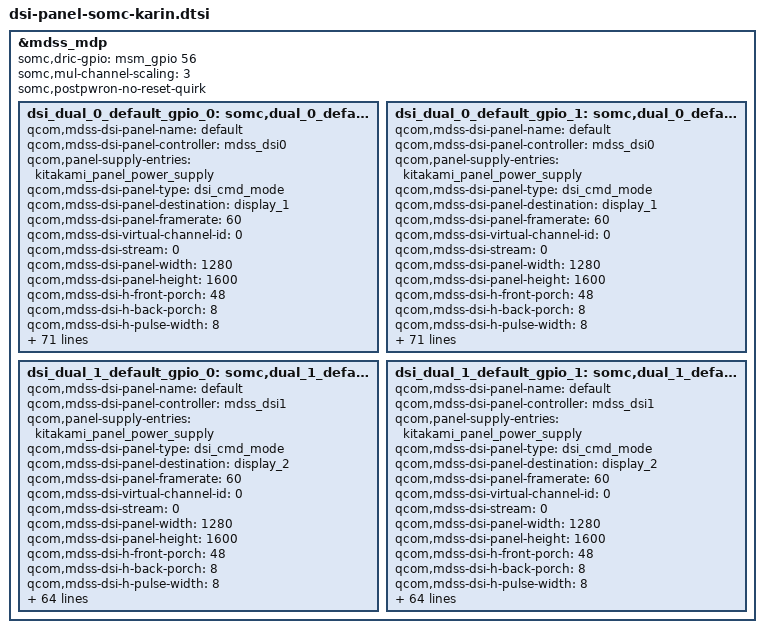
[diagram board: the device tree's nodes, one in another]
/* Copyright (c) 2013-2014, The Linux Foundation. All rights reserved.
 *
 * This program is free software; you can redistribute it and/or modify
 * it under the terms of the GNU General Public License version 2 and
 * only version 2 as published by the Free Software Foundation.
 *
 * This program is distributed in the hope that it will be useful,
 * but WITHOUT ANY WARRANTY; without even the implied warranty of
 * MERCHANTABILITY or FITNESS FOR A PARTICULAR PURPOSE.  See the
 * GNU General Public License for more details.
 */
/*
 * Copyright (C) 2015 Sony Mobile Communications Inc.
 *
 * This program is free software; you can redistribute it and/or modify
 * it under the terms of the GNU General Public License version 2, as
 * published by the Free Software Foundation.
 */

#include "dsi-panel-somc-novatek-jdi-uxga-cmd.dtsi"
#include "dsi-panel-somc-novatek-tianma-uxga-cmd.dtsi"

&mdss_mdp {
	somc,dric-gpio = <&msm_gpio 56 0>;
	somc,mul-channel-scaling = <3>;
	somc,postpwron-no-reset-quirk;
	dsi_dual_0_default_gpio_0: somc,dual_0_default_panel_0 {
		qcom,mdss-dsi-panel-name = "default";
		qcom,mdss-dsi-panel-controller = <&mdss_dsi0>;
		qcom,panel-supply-entries = <&kitakami_panel_power_supply>;
		qcom,mdss-dsi-panel-type = "dsi_cmd_mode";
		qcom,mdss-dsi-panel-destination = "display_1";
		qcom,mdss-dsi-panel-framerate = <60>;
		qcom,mdss-dsi-virtual-channel-id = <0>;
		qcom,mdss-dsi-stream = <0>;
		qcom,mdss-dsi-panel-width = <1280>;
		qcom,mdss-dsi-panel-height = <1600>;
		qcom,mdss-dsi-h-front-porch = <48>;
		qcom,mdss-dsi-h-back-porch = <8>;
		qcom,mdss-dsi-h-pulse-width = <8>;
		qcom,mdss-dsi-h-sync-skew = <0>;
		qcom,mdss-dsi-v-back-porch = <4>;
		qcom,mdss-dsi-v-front-porch = <246>;
		qcom,mdss-dsi-v-pulse-width = <4>;
		qcom,mdss-pan-physical-width-dimension = <216>;
		qcom,mdss-pan-physical-height-dimension = <135>;
		qcom,mdss-dsi-h-left-border = <0>;
		qcom,mdss-dsi-h-right-border = <0>;
		qcom,mdss-dsi-v-top-border = <0>;
		qcom,mdss-dsi-v-bottom-border = <0>;
		qcom,mdss-dsi-bpp = <24>;
		qcom,mdss-dsi-underflow-color = <0x0>;
		qcom,mdss-dsi-border-color = <0>;
		somc,mdss-dsi-init-command = [05 01 00 00 05 00 01 01
				23 01 00 00 00 00 02 B0 00
				29 01 00 00 00 00 06 B3 04 08 00 22 00
				23 01 00 00 00 00 02 B4 0C
				29 01 00 00 00 00 03 B6 3A D3
				23 01 00 00 00 00 02 C3 00
				23 01 00 00 00 00 02 D6 01
				15 01 00 00 00 00 02 3A 77
				39 01 00 00 00 00 05 2A 00 00 04 FF
				39 01 00 00 00 00 05 2B 00 00 06 3F
				15 01 00 00 00 00 02 35 00
				39 01 00 00 00 00 03 44 00 00
				05 01 00 00 64 00 01 11];
		qcom,mdss-dsi-on-command = [05 01 00 00 00 00 01 29];
		qcom,mdss-dsi-off-command = [05 01 00 00 14 00 01 28
				05 01 00 00 50 00 01 10];
		qcom,mdss-dsi-on-command-state = "dsi_lp_mode";
		qcom,mdss-dsi-off-command-state = "dsi_hs_mode";
		somc,mdss-dsi-touch-id-command = [06 01 00 01 05 00 01 A1];
		somc,mdss-dsi-touch-id-len = <7>;
		qcom,mdss-dsi-h-sync-pulse = <1>;
		qcom,mdss-dsi-traffic-mode = "non_burst_sync_event";
		qcom,mdss-dsi-bllp-eof-power-mode;
		qcom,mdss-dsi-bllp-power-mode;
		qcom,cmd-sync-wait-broadcast;
		qcom,mdss-dsi-lane-0-state;
		qcom,mdss-dsi-lane-1-state;
		qcom,mdss-dsi-lane-2-state;
		qcom,mdss-dsi-lane-3-state;
		qcom,mdss-dsi-te-pin-select = <1>;
		qcom,mdss-dsi-wr-mem-start = <0x2c>;
		qcom,mdss-dsi-wr-mem-continue = <0x3c>;
		qcom,mdss-dsi-te-dcs-command = <1>;
		qcom,mdss-dsi-te-check-enable;
		qcom,mdss-dsi-te-using-te-pin;
		qcom,mdss-dsi-panel-timings = [E6 38 26 00 68 66 32 3C 2C 03 04 00];
		qcom,mdss-dsi-t-clk-post = <0x1B>;
		qcom,mdss-dsi-t-clk-pre = <0x2B>;
		qcom,mdss-dsi-bl-min-level = <1>;
		qcom,mdss-dsi-bl-max-level = <4095>;
		qcom,mdss-brightness-max-level = <255>;
		qcom,mdss-dsi-dma-trigger = "trigger_sw";
		qcom,mdss-dsi-mdp-trigger = "none";
		qcom,mdss-dsi-bl-pmic-control-type = "bl_ctrl_wled";
		qcom,mdss-dsi-tx-eot-append;
		qcom,mdss-dsi-lp11-init;
		qcom,qpnp-lab-limit-maximum-current = <200>;
		qcom,qpnp-ibb-limit-maximum-current = <800>;

		somc,mdss-dsi-disp-on-in-hs = <1>;
		somc,mdss-dsi-wait-time-before-on-cmd = <0>;
		somc,platform-regulator-settings = [03 03 03 00 20 00 01];
		somc,mdss-dsi-lane-config = [02 00 ef 00 20 00 00 01 ff
				02 00 ef 00 40 00 00 01 ff
				02 00 ef 40 20 00 00 01 ff
				02 00 ef 40 00 00 00 01 ff
				00 00 00 80 00 00 00 01 97];
		somc,dsi-index = <0>;
		somc,mdss-dsi-slave;
		somc,lcd-id = <0>;
		somc,lcd-id-adc = <0 0x7fffffff>;
		somc,disp-en-on-pre = <5>;
		somc,pw-on-rst-seq = <0 10>, <1 10>;
		somc,disp-en-off-post = <80>;
		somc,pw-off-rst-seq = <0 0>;
		somc,lab-output-voltage = <5400000>;
		somc,ibb-output-voltage = <5400000>;
	};

	dsi_dual_0_default_gpio_1: somc,dual_0_default_panel_1 {
		qcom,mdss-dsi-panel-name = "default";
		qcom,mdss-dsi-panel-controller = <&mdss_dsi0>;
		qcom,panel-supply-entries = <&kitakami_panel_power_supply>;
		qcom,mdss-dsi-panel-type = "dsi_cmd_mode";
		qcom,mdss-dsi-panel-destination = "display_1";
		qcom,mdss-dsi-panel-framerate = <60>;
		qcom,mdss-dsi-virtual-channel-id = <0>;
		qcom,mdss-dsi-stream = <0>;
		qcom,mdss-dsi-panel-width = <1280>;
		qcom,mdss-dsi-panel-height = <1600>;
		qcom,mdss-dsi-h-front-porch = <48>;
		qcom,mdss-dsi-h-back-porch = <8>;
		qcom,mdss-dsi-h-pulse-width = <8>;
		qcom,mdss-dsi-h-sync-skew = <0>;
		qcom,mdss-dsi-v-back-porch = <4>;
		qcom,mdss-dsi-v-front-porch = <246>;
		qcom,mdss-dsi-v-pulse-width = <4>;
		qcom,mdss-pan-physical-width-dimension = <216>;
		qcom,mdss-pan-physical-height-dimension = <135>;
		qcom,mdss-dsi-h-left-border = <0>;
		qcom,mdss-dsi-h-right-border = <0>;
		qcom,mdss-dsi-v-top-border = <0>;
		qcom,mdss-dsi-v-bottom-border = <0>;
		qcom,mdss-dsi-bpp = <24>;
		qcom,mdss-dsi-underflow-color = <0x0>;
		qcom,mdss-dsi-border-color = <0>;
		somc,mdss-dsi-init-command = [05 01 00 00 05 00 01 01
				23 01 00 00 00 00 02 B0 00
				29 01 00 00 00 00 06 B3 04 08 00 22 00
				23 01 00 00 00 00 02 B4 0C
				29 01 00 00 00 00 03 B6 3A D3
				23 01 00 00 00 00 02 C3 00
				23 01 00 00 00 00 02 D6 01
				15 01 00 00 00 00 02 3A 77
				39 01 00 00 00 00 05 2A 00 00 04 FF
				39 01 00 00 00 00 05 2B 00 00 06 3F
				15 01 00 00 00 00 02 35 00
				39 01 00 00 00 00 03 44 00 00
				05 01 00 00 64 00 01 11];
		qcom,mdss-dsi-on-command = [05 01 00 00 00 00 01 29];
		qcom,mdss-dsi-off-command = [05 01 00 00 14 00 01 28
				05 01 00 00 50 00 01 10];
		qcom,mdss-dsi-on-command-state = "dsi_lp_mode";
		qcom,mdss-dsi-off-command-state = "dsi_hs_mode";
		somc,mdss-dsi-touch-id-command = [06 01 00 01 05 00 01 A1];
		somc,mdss-dsi-touch-id-len = <7>;
		qcom,mdss-dsi-h-sync-pulse = <1>;
		qcom,mdss-dsi-traffic-mode = "non_burst_sync_event";
		qcom,mdss-dsi-bllp-eof-power-mode;
		qcom,mdss-dsi-bllp-power-mode;
		qcom,cmd-sync-wait-broadcast;
		qcom,mdss-dsi-lane-0-state;
		qcom,mdss-dsi-lane-1-state;
		qcom,mdss-dsi-lane-2-state;
		qcom,mdss-dsi-lane-3-state;
		qcom,mdss-dsi-te-pin-select = <1>;
		qcom,mdss-dsi-wr-mem-start = <0x2c>;
		qcom,mdss-dsi-wr-mem-continue = <0x3c>;
		qcom,mdss-dsi-te-dcs-command = <1>;
		qcom,mdss-dsi-te-check-enable;
		qcom,mdss-dsi-te-using-te-pin;
		qcom,mdss-dsi-panel-timings = [E6 38 26 00 68 66 32 3C 2C 03 04 00];
		qcom,mdss-dsi-t-clk-post = <0x1B>;
		qcom,mdss-dsi-t-clk-pre = <0x2B>;
		qcom,mdss-dsi-bl-min-level = <1>;
		qcom,mdss-dsi-bl-max-level = <4095>;
		qcom,mdss-brightness-max-level = <255>;
		qcom,mdss-dsi-dma-trigger = "trigger_sw";
		qcom,mdss-dsi-mdp-trigger = "none";
		qcom,mdss-dsi-bl-pmic-control-type = "bl_ctrl_wled";
		qcom,mdss-dsi-tx-eot-append;
		qcom,mdss-dsi-lp11-init;
		qcom,qpnp-lab-limit-maximum-current = <200>;
		qcom,qpnp-ibb-limit-maximum-current = <800>;

		somc,mdss-dsi-disp-on-in-hs = <1>;
		somc,mdss-dsi-wait-time-before-on-cmd = <0>;
		somc,platform-regulator-settings = [03 03 03 00 20 00 01];
		somc,mdss-dsi-lane-config = [02 00 ef 00 20 00 00 01 ff
				02 00 ef 00 40 00 00 01 ff
				02 00 ef 40 20 00 00 01 ff
				02 00 ef 40 00 00 00 01 ff
				00 00 00 80 00 00 00 01 97];
		somc,dsi-index = <0>;
		somc,mdss-dsi-slave;
		somc,lcd-id = <1>;
		somc,lcd-id-adc = <0 0x7fffffff>;
		somc,disp-en-on-pre = <5>;
		somc,pw-on-rst-seq = <0 10>, <1 10>;
		somc,disp-en-off-post = <80>;
		somc,pw-off-rst-seq = <0 0>;
		somc,lab-output-voltage = <5400000>;
		somc,ibb-output-voltage = <5400000>;
	};

	dsi_dual_1_default_gpio_0: somc,dual_1_default_panel_0 {
		qcom,mdss-dsi-panel-name = "default";
		qcom,mdss-dsi-panel-controller = <&mdss_dsi1>;
		qcom,panel-supply-entries = <&kitakami_panel_power_supply>;
		qcom,mdss-dsi-panel-type = "dsi_cmd_mode";
		qcom,mdss-dsi-panel-destination = "display_2";
		qcom,mdss-dsi-panel-framerate = <60>;
		qcom,mdss-dsi-virtual-channel-id = <0>;
		qcom,mdss-dsi-stream = <0>;
		qcom,mdss-dsi-panel-width = <1280>;
		qcom,mdss-dsi-panel-height = <1600>;
		qcom,mdss-dsi-h-front-porch = <48>;
		qcom,mdss-dsi-h-back-porch = <8>;
		qcom,mdss-dsi-h-pulse-width = <8>;
		qcom,mdss-dsi-h-sync-skew = <0>;
		qcom,mdss-dsi-v-back-porch = <4>;
		qcom,mdss-dsi-v-front-porch = <246>;
		qcom,mdss-dsi-v-pulse-width = <4>;
		qcom,mdss-pan-physical-width-dimension = <216>;
		qcom,mdss-pan-physical-height-dimension = <135>;
		qcom,mdss-dsi-h-left-border = <0>;
		qcom,mdss-dsi-h-right-border = <0>;
		qcom,mdss-dsi-v-top-border = <0>;
		qcom,mdss-dsi-v-bottom-border = <0>;
		qcom,mdss-dsi-bpp = <24>;
		qcom,mdss-dsi-underflow-color = <0x0>;
		qcom,mdss-dsi-border-color = <0>;
		somc,mdss-dsi-init-command = [05 01 00 00 05 00 01 01
				23 01 00 00 00 00 02 B0 00
				29 01 00 00 00 00 06 B3 04 08 00 22 00
				23 01 00 00 00 00 02 B4 0C
				29 01 00 00 00 00 03 B6 3A D3
				23 01 00 00 00 00 02 C3 00
				23 01 00 00 00 00 02 D6 01
				15 01 00 00 00 00 02 3A 77
				39 01 00 00 00 00 05 2A 00 00 04 FF
				39 01 00 00 00 00 05 2B 00 00 06 3F
				15 01 00 00 00 00 02 35 00
				39 01 00 00 00 00 03 44 00 00
				05 01 00 00 64 00 01 11];
		qcom,mdss-dsi-on-command = [05 01 00 00 00 00 01 29];
		qcom,mdss-dsi-off-command = [05 01 00 00 14 00 01 28
				05 01 00 00 50 00 01 10];
		qcom,mdss-dsi-on-command-state = "dsi_lp_mode";
		qcom,mdss-dsi-off-command-state = "dsi_hs_mode";
		somc,mdss-dsi-touch-id-command = [06 01 00 01 05 00 01 A1];
		somc,mdss-dsi-touch-id-len = <7>;
		qcom,mdss-dsi-h-sync-pulse = <1>;
		qcom,mdss-dsi-traffic-mode = "non_burst_sync_event";
		qcom,mdss-dsi-bllp-eof-power-mode;
		qcom,mdss-dsi-bllp-power-mode;
		qcom,cmd-sync-wait-broadcast;
		qcom,cmd-sync-wait-trigger;
		qcom,mdss-dsi-lane-0-state;
		qcom,mdss-dsi-lane-1-state;
		qcom,mdss-dsi-lane-2-state;
		qcom,mdss-dsi-lane-3-state;
		qcom,mdss-dsi-te-pin-select = <1>;
		qcom,mdss-dsi-wr-mem-start = <0x2c>;
		qcom,mdss-dsi-wr-mem-continue = <0x3c>;
		qcom,mdss-dsi-te-dcs-command = <1>;
		qcom,mdss-dsi-te-check-enable;
		qcom,mdss-dsi-te-using-te-pin;
		qcom,mdss-dsi-panel-timings = [E6 38 26 00 68 66 32 3C 2C 03 04 00];
		qcom,mdss-dsi-t-clk-post = <0x1B>;
		qcom,mdss-dsi-t-clk-pre = <0x2B>;
		qcom,mdss-dsi-bl-min-level = <1>;
		qcom,mdss-dsi-bl-max-level = <4095>;
		qcom,mdss-brightness-max-level = <255>;
		qcom,mdss-dsi-dma-trigger = "trigger_sw";
		qcom,mdss-dsi-mdp-trigger = "none";
		qcom,mdss-dsi-tx-eot-append;
		qcom,mdss-dsi-lp11-init;
		qcom,qpnp-lab-limit-maximum-current = <200>;
		qcom,qpnp-ibb-limit-maximum-current = <800>;

		somc,mdss-dsi-disp-on-in-hs = <1>;
		somc,platform-regulator-settings = [03 03 03 00 20 00 01];
		somc,mdss-dsi-lane-config = [02 00 ef 00 20 00 00 01 ff
				02 00 ef 00 40 00 00 01 ff
				02 00 ef 40 20 00 00 01 ff
				02 00 ef 40 00 00 00 01 ff
				00 00 00 80 00 00 00 01 97];
		somc,dsi-index = <1>;
		somc,lcd-id = <0>;
		somc,lcd-id-adc = <0 0x7fffffff>;
		somc,lab-output-voltage = <5400000>;
		somc,ibb-output-voltage = <5400000>;
	};

	dsi_dual_1_default_gpio_1: somc,dual_1_default_panel_1 {
		qcom,mdss-dsi-panel-name = "default";
		qcom,mdss-dsi-panel-controller = <&mdss_dsi1>;
		qcom,panel-supply-entries = <&kitakami_panel_power_supply>;
		qcom,mdss-dsi-panel-type = "dsi_cmd_mode";
		qcom,mdss-dsi-panel-destination = "display_2";
		qcom,mdss-dsi-panel-framerate = <60>;
		qcom,mdss-dsi-virtual-channel-id = <0>;
		qcom,mdss-dsi-stream = <0>;
		qcom,mdss-dsi-panel-width = <1280>;
		qcom,mdss-dsi-panel-height = <1600>;
		qcom,mdss-dsi-h-front-porch = <48>;
		qcom,mdss-dsi-h-back-porch = <8>;
		qcom,mdss-dsi-h-pulse-width = <8>;
		qcom,mdss-dsi-h-sync-skew = <0>;
		qcom,mdss-dsi-v-back-porch = <4>;
		qcom,mdss-dsi-v-front-porch = <246>;
		qcom,mdss-dsi-v-pulse-width = <4>;
		qcom,mdss-pan-physical-width-dimension = <216>;
		qcom,mdss-pan-physical-height-dimension = <135>;
		qcom,mdss-dsi-h-left-border = <0>;
		qcom,mdss-dsi-h-right-border = <0>;
		qcom,mdss-dsi-v-top-border = <0>;
		qcom,mdss-dsi-v-bottom-border = <0>;
		qcom,mdss-dsi-bpp = <24>;
		qcom,mdss-dsi-underflow-color = <0x0>;
		qcom,mdss-dsi-border-color = <0>;
		somc,mdss-dsi-init-command = [05 01 00 00 05 00 01 01
				23 01 00 00 00 00 02 B0 00
				29 01 00 00 00 00 06 B3 04 08 00 22 00
				23 01 00 00 00 00 02 B4 0C
				29 01 00 00 00 00 03 B6 3A D3
				23 01 00 00 00 00 02 C3 00
				23 01 00 00 00 00 02 D6 01
				15 01 00 00 00 00 02 3A 77
				39 01 00 00 00 00 05 2A 00 00 04 FF
				39 01 00 00 00 00 05 2B 00 00 06 3F
				15 01 00 00 00 00 02 35 00
				39 01 00 00 00 00 03 44 00 00
				05 01 00 00 64 00 01 11];
		qcom,mdss-dsi-on-command = [05 01 00 00 00 00 01 29];
		qcom,mdss-dsi-off-command = [05 01 00 00 14 00 01 28
				05 01 00 00 50 00 01 10];
		qcom,mdss-dsi-on-command-state = "dsi_lp_mode";
		qcom,mdss-dsi-off-command-state = "dsi_hs_mode";
		somc,mdss-dsi-touch-id-command = [06 01 00 01 05 00 01 A1];
		somc,mdss-dsi-touch-id-len = <7>;
		qcom,mdss-dsi-h-sync-pulse = <1>;
		qcom,mdss-dsi-traffic-mode = "non_burst_sync_event";
		qcom,mdss-dsi-bllp-eof-power-mode;
		qcom,mdss-dsi-bllp-power-mode;
		qcom,cmd-sync-wait-broadcast;
		qcom,cmd-sync-wait-trigger;
		qcom,mdss-dsi-lane-0-state;
		qcom,mdss-dsi-lane-1-state;
		qcom,mdss-dsi-lane-2-state;
		qcom,mdss-dsi-lane-3-state;
		qcom,mdss-dsi-te-pin-select = <1>;
		qcom,mdss-dsi-wr-mem-start = <0x2c>;
		qcom,mdss-dsi-wr-mem-continue = <0x3c>;
		qcom,mdss-dsi-te-dcs-command = <1>;
		qcom,mdss-dsi-te-check-enable;
		qcom,mdss-dsi-te-using-te-pin;
		qcom,mdss-dsi-panel-timings = [E6 38 26 00 68 66 32 3C 2C 03 04 00];
		qcom,mdss-dsi-t-clk-post = <0x1B>;
		qcom,mdss-dsi-t-clk-pre = <0x2B>;
		qcom,mdss-dsi-bl-min-level = <1>;
		qcom,mdss-dsi-bl-max-level = <4095>;
		qcom,mdss-brightness-max-level = <255>;
		qcom,mdss-dsi-dma-trigger = "trigger_sw";
		qcom,mdss-dsi-mdp-trigger = "none";
		qcom,mdss-dsi-tx-eot-append;
		qcom,mdss-dsi-lp11-init;
		qcom,qpnp-lab-limit-maximum-current = <200>;
		qcom,qpnp-ibb-limit-maximum-current = <800>;

		somc,mdss-dsi-disp-on-in-hs = <1>;
		somc,platform-regulator-settings = [03 03 03 00 20 00 01];
		somc,mdss-dsi-lane-config = [02 00 ef 00 20 00 00 01 ff
				02 00 ef 00 40 00 00 01 ff
				02 00 ef 40 20 00 00 01 ff
				02 00 ef 40 00 00 00 01 ff
				00 00 00 80 00 00 00 01 97];
		somc,dsi-index = <1>;
		somc,lcd-id = <1>;
		somc,lcd-id-adc = <0 0x7fffffff>;
		somc,lab-output-voltage = <5400000>;
		somc,ibb-output-voltage = <5400000>;
	};
};
